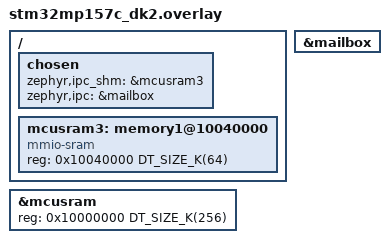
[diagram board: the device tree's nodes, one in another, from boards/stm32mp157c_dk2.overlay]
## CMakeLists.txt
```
cmake_minimum_required(VERSION 3.20.0)

find_package(Zephyr REQUIRED HINTS $ENV{ZEPHYR_BASE})
project(px4_safety_monitor LANGUAGES C)

set(MAVLINK_DIR ${CMAKE_CURRENT_SOURCE_DIR}/../third_party/c_library_v2)

target_include_directories(app PRIVATE
  include
  ${MAVLINK_DIR}
  ${LIBMETAL_INCLUDE_DIR}
  ${OPENAMP_INCLUDE_DIR}
  ${PLATFORM_DIR}
)
target_compile_options(app PRIVATE -Wno-address-of-packed-member)

target_sources(app PRIVATE
  src/main_zephyr.c
  src/transport_rpmsg.c
  src/monitor.c
  src/params.c
  src/mavlink_rx.c
  src/state.c
  src/arbiter.c
  src/override_tx.c
  src/rules/geofence.c
  src/rules/envelope.c
  src/rules/battery.c
  src/rules/liveness.c
)
```

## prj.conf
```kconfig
CONFIG_IPM=y
CONFIG_OPENAMP=y
CONFIG_OPENAMP_RSC_TABLE=y
CONFIG_OPENAMP_RSC_TABLE_NUM_RPMSG_BUFF=8
CONFIG_OPENAMP_MASTER=n
# libmetal allocates its device list from the kernel heap at init. The
# monitor itself never allocates.
CONFIG_HEAP_MEM_POOL_SIZE=1024

CONFIG_FPU=y
# The RX thread and the periodic task both use floats and one preempts the other.
CONFIG_FPU_SHARING=y
CONFIG_PICOLIBC=y
CONFIG_MAIN_STACK_SIZE=2048

# Console in the remoteproc trace buffer, read from the A7. No UART.
CONFIG_RAM_CONSOLE=y
CONFIG_RAM_CONSOLE_BUFFER_SIZE=2048
CONFIG_CONSOLE=y
CONFIG_SERIAL=n
CONFIG_UART_CONSOLE=n
CONFIG_LOG=y
CONFIG_LOG_MODE_MINIMAL=y
CONFIG_LOG_DEFAULT_LEVEL=2
CONFIG_CBPRINTF_NANO=y

CONFIG_ASSERT=n
```

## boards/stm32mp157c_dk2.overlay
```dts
/*
 * The vrings and rpmsg buffers live in SRAM3, matching the vdev0vring0,
 * vdev0vring1 and vdev0buffer reserved-memory nodes of the OpenSTLinux device
 * tree. Zephyr's RAM stops short of them.
 */
/ {
	chosen {
		zephyr,ipc_shm = &mcusram3;
		zephyr,ipc = &mailbox;
	};

	mcusram3: memory1@10040000 {
		compatible = "mmio-sram";
		reg = <0x10040000 DT_SIZE_K(64)>;
	};
};

&mcusram {
	reg = <0x10000000 DT_SIZE_K(256)>;
};

&mailbox {
	status = "okay";
};
```

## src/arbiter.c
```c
#include "monitor/arbiter.h"
#include "monitor/mav.h"

void arbiter_init(struct arbiter *a)
{
	*a = (struct arbiter){.active = ACTION_NONE};
}

uint16_t arbiter_command(enum action action)
{
	switch (action) {
	case ACTION_RTL:
		return MAV_CMD_NAV_RETURN_TO_LAUNCH;
	case ACTION_LAND:
		return MAV_CMD_NAV_LAND;
	case ACTION_TERMINATE:
		return MAV_CMD_COMPONENT_ARM_DISARM;
	default:
		return 0;
	}
}

static void activate(struct arbiter *a, enum action action, uint32_t now)
{
	a->active = action;
	a->active_since_ms = now;
	a->unacked_tx = 0;
	a->acked = false;
}

static bool ack_is_rejection(uint8_t result)
{
	return result != MAV_RESULT_ACCEPTED && result != MAV_RESULT_IN_PROGRESS;
}

bool arbiter_step(struct arbiter *a, enum action wanted, const struct vehicle_state *s,
		  uint32_t now, const struct monitor_params *p)
{
	if (a->active != ACTION_NONE && !s->armed) {
		arbiter_init(a);
	}
	if (a->active == ACTION_NONE && wanted == ACTION_NONE) {
		return false;
	}

	if (wanted > a->active) {
		activate(a, wanted, now);
		a->last_tx_ms = now;
		a->unacked_tx = 1;
		return true;
	}

	bool ack_current = s->have_ack && s->ack_command == arbiter_command(a->active) &&
			   (int32_t)(s->ack_ms - a->active_since_ms) >= 0;

	if (ack_current && !ack_is_rejection(s->ack_result)) {
		a->acked = true;
	}
	bool rejected = ack_current && !a->acked && ack_is_rejection(s->ack_result);
	bool ignored = !a->acked && a->unacked_tx >= p->max_unacked_tx &&
		       now - a->last_tx_ms >= p->retransmit_ms;

	if ((rejected || ignored) && a->active < ACTION_TERMINATE) {
		activate(a, a->active + 1, now);
		a->last_tx_ms = now;
		a->unacked_tx = 1;
		return true;
	}

	/* Termination repeats until disarm is seen: an ack alone did not stop the motors. */
	if ((!a->acked || a->active == ACTION_TERMINATE) && now - a->last_tx_ms >= p->retransmit_ms) {
		a->last_tx_ms = now;
		if (a->unacked_tx < UINT8_MAX) {
			a->unacked_tx++;
		}
		return true;
	}
	return false;
}
```

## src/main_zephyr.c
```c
#include <zephyr/kernel.h>

#include "monitor/monitor.h"
#include "monitor/platform.h"
#include "transport_rpmsg.h"

static K_MUTEX_DEFINE(state_lock);

uint32_t plat_now_ms(void)
{
	return k_uptime_get_32();
}

void plat_tx(const uint8_t *buf, size_t len)
{
	transport_rpmsg_send(buf, len);
}

void plat_lock(void)
{
	k_mutex_lock(&state_lock, K_FOREVER);
}

void plat_unlock(void)
{
	k_mutex_unlock(&state_lock);
}

int main(void)
{
	monitor_init();
	transport_rpmsg_start();

	/* Absolute deadlines, so a late tick does not push back the ones after it. */
	int64_t next = k_uptime_get();

	for (;;) {
		monitor_tick();
		next += MONITOR_TICK_MS;
		k_sleep(K_TIMEOUT_ABS_MS(next));
	}
}
```

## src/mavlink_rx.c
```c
#include "monitor/mav.h"
#include "monitor/mavlink_rx.h"
#include "monitor/state.h"

static void dispatch(struct vehicle_state *s, const mavlink_message_t *msg, uint32_t now,
		     const struct monitor_params *p)
{
	switch (msg->msgid) {
	case MAVLINK_MSG_ID_HEARTBEAT: {
		mavlink_heartbeat_t m;

		mavlink_msg_heartbeat_decode(msg, &m);
		state_on_heartbeat(s, (m.base_mode & MAV_MODE_FLAG_SAFETY_ARMED) != 0,
				   m.custom_mode);
		break;
	}
	case MAVLINK_MSG_ID_EXTENDED_SYS_STATE:
		state_on_landed(s, mavlink_msg_extended_sys_state_get_landed_state(msg));
		break;
	case MAVLINK_MSG_ID_ATTITUDE: {
		mavlink_attitude_t m;

		mavlink_msg_attitude_decode(msg, &m);
		state_on_attitude(s, m.roll, m.pitch, now, p);
		break;
	}
	case MAVLINK_MSG_ID_GLOBAL_POSITION_INT: {
		mavlink_global_position_int_t m;

		mavlink_msg_global_position_int_decode(msg, &m);
		state_on_position(s, m.lat, m.lon, m.relative_alt, m.vz, now, p);
		break;
	}
	case MAVLINK_MSG_ID_SYS_STATUS:
		state_on_battery(s, mavlink_msg_sys_status_get_battery_remaining(msg));
		break;
	case MAVLINK_MSG_ID_COMMAND_ACK: {
		mavlink_command_ack_t m;

		mavlink_msg_command_ack_decode(msg, &m);
		state_on_ack(s, m.command, m.result, now);
		break;
	}
	default:
		break;
	}
}

void mavlink_rx_feed(struct vehicle_state *s, const uint8_t *buf, size_t len, uint32_t now,
		     const struct monitor_params *p)
{
	static mavlink_message_t msg;
	static mavlink_status_t status;

	for (size_t i = 0; i < len; i++) {
		if (!mavlink_parse_char(MAVLINK_COMM_0, buf[i], &msg, &status)) {
			continue;
		}
		/* GCS, gimbal and camera components share the link and also send heartbeats. */
		if (msg.sysid == AUTOPILOT_SYSID && msg.compid == AUTOPILOT_COMPID) {
			dispatch(s, &msg, now, p);
		}
	}
}
```

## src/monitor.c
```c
#include "monitor/arbiter.h"
#include "monitor/mavlink_rx.h"
#include "monitor/monitor.h"
#include "monitor/override_tx.h"
#include "monitor/platform.h"
#include "monitor/rules.h"
#include "monitor/state.h"

#define HEARTBEAT_TICKS (1000 / MONITOR_TICK_MS)

static struct vehicle_state state;
static struct arbiter arbiter;
static enum action reported;
static uint32_t tick_count;

void monitor_init(void)
{
	state_init(&state);
	arbiter_init(&arbiter);
	reported = ACTION_NONE;
	tick_count = 0;
}

void monitor_rx_bytes(const uint8_t *buf, size_t len)
{
	uint32_t now = plat_now_ms();

	plat_lock();
	mavlink_rx_feed(&state, buf, len, now, &monitor_default_params);
	plat_unlock();
}

void monitor_tick(void)
{
	const struct monitor_params *p = &monitor_default_params;
	struct vehicle_state snap;
	uint32_t now = plat_now_ms();

	plat_lock();
	snap = state;
	plat_unlock();

	const enum action verdicts[RULE_COUNT] = {
		[RULE_GEOFENCE] = rule_geofence(&snap, now, p),
		[RULE_ENVELOPE] = rule_envelope(&snap, now, p),
		[RULE_BATTERY] = rule_battery(&snap, now, p),
		[RULE_LIVENESS] = rule_liveness(&snap, now, p),
	};
	enum action wanted = ACTION_NONE;
	uint8_t mask = 0;

	for (int i = 0; i < RULE_COUNT; i++) {
		if (verdicts[i] != ACTION_NONE) {
			mask |= (uint8_t)(1u << i);
		}
		if (verdicts[i] > wanted) {
			wanted = verdicts[i];
		}
	}

	if (arbiter_step(&arbiter, wanted, &snap, now, p)) {
		override_tx_command(arbiter.active, arbiter.unacked_tx - 1);
	}
	if (arbiter.active != reported) {
		reported = arbiter.active;
		override_tx_report(reported, mask, now);
	}
	if (tick_count++ % HEARTBEAT_TICKS == 0) {
		override_tx_heartbeat();
	}
}
```

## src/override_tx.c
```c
#include <string.h>

#include "monitor/arbiter.h"
#include "monitor/mav.h"
#include "monitor/override_tx.h"
#include "monitor/platform.h"

#define FORCE_DISARM_MAGIC 21196.0f

static void send(const mavlink_message_t *msg)
{
	uint8_t buf[MAVLINK_MAX_PACKET_LEN];
	uint16_t len = mavlink_msg_to_send_buffer(buf, msg);

	plat_tx(buf, len);
}

void override_tx_command(enum action action, uint8_t confirmation)
{
	mavlink_message_t msg;
	float param2 = 0.0f;

	if (action == ACTION_TERMINATE) {
		param2 = FORCE_DISARM_MAGIC;
	}
	mavlink_msg_command_long_pack_chan(MONITOR_SYSID, MONITOR_COMPID, MAVLINK_COMM_1, &msg,
					   AUTOPILOT_SYSID, AUTOPILOT_COMPID,
					   arbiter_command(action), confirmation, 0.0f, param2,
					   0.0f, 0.0f, 0.0f, 0.0f, 0.0f);
	send(&msg);
}

void override_tx_heartbeat(void)
{
	mavlink_message_t msg;

	mavlink_msg_heartbeat_pack_chan(MONITOR_SYSID, MONITOR_COMPID, MAVLINK_COMM_1, &msg,
					MAV_TYPE_ONBOARD_CONTROLLER, MAV_AUTOPILOT_INVALID, 0, 0,
					MAV_STATE_ACTIVE);
	send(&msg);
}

void override_tx_report(enum action action, uint8_t rule_mask, uint32_t now)
{
	mavlink_message_t msg;
	char name[MAVLINK_MSG_NAMED_VALUE_INT_FIELD_NAME_LEN] = "MON_ACT";

	mavlink_msg_named_value_int_pack_chan(MONITOR_SYSID, MONITOR_COMPID, MAVLINK_COMM_1, &msg,
					      now, name,
					      (int32_t)action | ((int32_t)rule_mask << 8));
	send(&msg);
}
```

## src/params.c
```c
#include "monitor/monitor.h"

/*
 * Compiled in and versioned, so a changed limit shows up in review. Rationale for
 * each number is in docs/requirements.md.
 *
 * Fence origin is the Gazebo default world's home position.
 */
static const struct fence_vertex fence[] = {
	{-60.0f, -60.0f},
	{60.0f, -60.0f},
	{60.0f, 60.0f},
	{-60.0f, 60.0f},
};

const struct monitor_params monitor_default_params = {
	.origin_lat_e7 = 473979711,
	.origin_lon_e7 = 85461637,
	.m_per_lon_e7 = 0.0075259f, /* 0.011131949 * cos(47.3977 deg) */
	.fence = fence,
	.fence_len = sizeof(fence) / sizeof(fence[0]),
	.fence_max_alt_m = 40.0f,
	.fence_hard_margin_m = 30.0f,
	.fence_samples = 2,
	.position_stale_ms = 1000,

	.tilt_limit_rad = 0.7854f,
	.tilt_samples = 5,
	.descent_limit_mps = 6.0f,
	.descent_samples = 5,
	.terminate_below_alt_m = 5.0f,

	.cruise_mps = 5.0f,
	.descend_mps = 1.5f,
	.battery_pct_per_s = 0.2f,
	.battery_margin = 0.2f,

	.liveness_timeout_ms = 300,

	.retransmit_ms = 200,
	.max_unacked_tx = 3,
};
```

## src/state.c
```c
#include <math.h>

#include "monitor/mav.h"
#include "monitor/rules.h"
#include "monitor/state.h"

#define AIRBORNE_ALT_M 1.0f

static uint8_t count_sample(uint8_t count, bool violated)
{
	if (!violated) {
		return 0;
	}
	return count == UINT8_MAX ? count : count + 1;
}

void state_init(struct vehicle_state *s)
{
	*s = (struct vehicle_state){.battery_pct = -1};
}

void state_on_heartbeat(struct vehicle_state *s, bool armed, uint32_t custom_mode)
{
	if (armed && !s->armed) {
		s->want_home = true;
		s->have_home = false;
	}
	s->have_heartbeat = true;
	s->armed = armed;
	s->custom_mode = custom_mode;
}

void state_on_landed(struct vehicle_state *s, uint8_t landed_state)
{
	s->landed_state = landed_state;
}

void state_on_attitude(struct vehicle_state *s, float roll, float pitch, uint32_t now,
		       const struct monitor_params *p)
{
	/* !(x <= limit) rather than x > limit, so a NaN from a bad sensor counts. */
	bool ok = fabsf(roll) <= p->tilt_limit_rad && fabsf(pitch) <= p->tilt_limit_rad;

	s->have_attitude = true;
	s->attitude_ms = now;
	s->roll_rad = roll;
	s->pitch_rad = pitch;
	s->tilt_over_count = count_sample(s->tilt_over_count, !ok);
}

void state_on_position(struct vehicle_state *s, int32_t lat_e7, int32_t lon_e7, int32_t rel_alt_mm,
		       int16_t vz_cms, uint32_t now, const struct monitor_params *p)
{
	s->have_position = true;
	s->position_ms = now;
	s->lat_e7 = lat_e7;
	s->lon_e7 = lon_e7;
	s->rel_alt_m = (float)rel_alt_mm / 1000.0f;
	s->down_mps = (float)vz_cms / 100.0f;

	s->descent_over_count =
		count_sample(s->descent_over_count, s->down_mps > p->descent_limit_mps);
	s->fence_excess_m = geofence_excess_m(lat_e7, lon_e7, s->rel_alt_m, p);
	s->fence_out_count = count_sample(s->fence_out_count, s->fence_excess_m > 0.0f);

	if (s->want_home) {
		s->want_home = false;
		s->have_home = true;
		s->home_lat_e7 = lat_e7;
		s->home_lon_e7 = lon_e7;
	}
}

void state_on_battery(struct vehicle_state *s, int8_t pct)
{
	s->have_battery = pct >= 0;
	s->battery_pct = pct;
}

void state_on_ack(struct vehicle_state *s, uint16_t command, uint8_t result, uint32_t now)
{
	s->have_ack = true;
	s->ack_ms = now;
	s->ack_command = command;
	s->ack_result = result;
}

bool state_airborne(const struct vehicle_state *s)
{
	if (!s->armed) {
		return false;
	}
	/*
	 * The landed state arrives at about 1 Hz, so altitude covers the gap
	 * right after liftoff and a land detector that is wrong on the way down.
	 */
	return s->landed_state == MAV_LANDED_STATE_IN_AIR ||
	       s->landed_state == MAV_LANDED_STATE_LANDING ||
	       (s->have_position && s->rel_alt_m > AIRBORNE_ALT_M);
}
```

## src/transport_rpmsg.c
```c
/*
 * rpmsg-tty endpoint: Linux turns the name service announcement into
 * /dev/ttyRPMSG0. Setup follows samples/subsys/ipc/openamp_rsc_table.
 */
#include <zephyr/device.h>
#include <zephyr/drivers/ipm.h>
#include <zephyr/kernel.h>
#include <zephyr/logging/log.h>

#include <addr_translation.h>
#include <metal/device.h>
#include <metal/io.h>
#include <metal/sys.h>
#include <openamp/open_amp.h>
#include <resource_table.h>

#include "monitor/monitor.h"
#include "transport_rpmsg.h"

LOG_MODULE_REGISTER(transport);

#define SHM_NODE DT_CHOSEN(zephyr_ipc_shm)
#define SHM_START_ADDR DT_REG_ADDR(SHM_NODE)
#define SHM_SIZE DT_REG_SIZE(SHM_NODE)

#define RPMSG_STACK_SIZE 1536
#define RPMSG_PRIORITY K_PRIO_PREEMPT(1)

static K_THREAD_STACK_DEFINE(rpmsg_stack, RPMSG_STACK_SIZE);
static struct k_thread rpmsg_thread;
static K_SEM_DEFINE(doorbell, 0, 1);

static const struct device *const ipm = DEVICE_DT_GET(DT_CHOSEN(zephyr_ipc));

static metal_phys_addr_t shm_physmap = SHM_START_ADDR;
static metal_phys_addr_t rsc_physmap;
static struct metal_io_region shm_io;
static struct metal_io_region rsc_io;
static struct rpmsg_virtio_device rvdev;
static struct rpmsg_endpoint tty_ept;
static void *rsc_table;

static void ipm_callback(const struct device *dev, void *context, uint32_t id,
			 volatile void *data)
{
	k_sem_give(&doorbell);
}

static int mailbox_notify(void *priv, uint32_t id)
{
	ipm_send(ipm, 0, id, &id, 4);
	return 0;
}

static int tty_rx(struct rpmsg_endpoint *ept, void *data, size_t len, uint32_t src, void *priv)
{
	monitor_rx_bytes(data, len);
	return RPMSG_SUCCESS;
}

static int platform_init(void)
{
	struct metal_init_params params = METAL_INIT_DEFAULTS;
	int rsc_size;

	if (metal_init(&params)) {
		return -EIO;
	}
	metal_io_init(&shm_io, (void *)SHM_START_ADDR, &shm_physmap, SHM_SIZE, -1, 0,
		      addr_translation_get_ops(shm_physmap));

	rsc_table_get(&rsc_table, &rsc_size);
	rsc_physmap = (uintptr_t)rsc_table;
	metal_io_init(&rsc_io, rsc_table, &rsc_physmap, rsc_size, -1, 0, NULL);

	if (!device_is_ready(ipm)) {
		return -ENODEV;
	}
	ipm_register_callback(ipm, ipm_callback, NULL);
	return ipm_set_enabled(ipm, 1);
}

static int create_vdev(void)
{
	struct virtio_device *vdev;
	struct fw_rsc_vdev_vring *vring;

	vdev = rproc_virtio_create_vdev(VIRTIO_DEV_DEVICE, VDEV_ID, rsc_table_to_vdev(rsc_table),
					&rsc_io, NULL, mailbox_notify, NULL);
	if (vdev == NULL) {
		return -ENOMEM;
	}
	rproc_virtio_wait_remote_ready(vdev);

	vring = rsc_table_get_vring0(rsc_table);
	if (rproc_virtio_init_vring(vdev, 0, vring->notifyid, (void *)vring->da, &rsc_io,
				    vring->num, vring->align)) {
		return -EIO;
	}
	vring = rsc_table_get_vring1(rsc_table);
	if (rproc_virtio_init_vring(vdev, 1, vring->notifyid, (void *)vring->da, &rsc_io,
				    vring->num, vring->align)) {
		return -EIO;
	}
	return rpmsg_init_vdev(&rvdev, vdev, NULL, &shm_io, NULL);
}

static void rpmsg_main(void *a, void *b, void *c)
{
	int ret = platform_init();

	ret = ret ? ret : create_vdev();
	ret = ret ? ret
		  : rpmsg_create_ept(&tty_ept, rpmsg_virtio_get_rpmsg_device(&rvdev), "rpmsg-tty",
				     RPMSG_ADDR_ANY, RPMSG_ADDR_ANY, tty_rx, NULL);
	if (ret) {
		/* The periodic task keeps running; with no input the monitor stays idle. */
		LOG_ERR("rpmsg setup failed: %d", ret);
		return;
	}
	LOG_INF("rpmsg-tty up");

	for (;;) {
		k_sem_take(&doorbell, K_FOREVER);
		rproc_virtio_notified(rvdev.vdev, VRING1_ID);
	}
}

int transport_rpmsg_start(void)
{
	k_thread_create(&rpmsg_thread, rpmsg_stack, RPMSG_STACK_SIZE, rpmsg_main, NULL, NULL, NULL,
			RPMSG_PRIORITY, 0, K_NO_WAIT);
	return 0;
}

void transport_rpmsg_send(const uint8_t *buf, size_t len)
{
	/*
	 * trysend, never send: the blocking call waits for a free vring buffer
	 * and would stall rule evaluation behind a Linux that stopped reading.
	 * Fails until Linux has written once, because only then is the
	 * destination address known. Telemetry does that well before takeoff.
	 */
	(void)rpmsg_trysend(&tty_ept, buf, (int)len);
}
```

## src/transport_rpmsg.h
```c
#ifndef TRANSPORT_RPMSG_H
#define TRANSPORT_RPMSG_H

#include <stddef.h>
#include <stdint.h>

/* Starts the virtio/rpmsg thread. Received bytes go to monitor_rx_bytes(). */
int transport_rpmsg_start(void);
void transport_rpmsg_send(const uint8_t *buf, size_t len);

#endif
```
